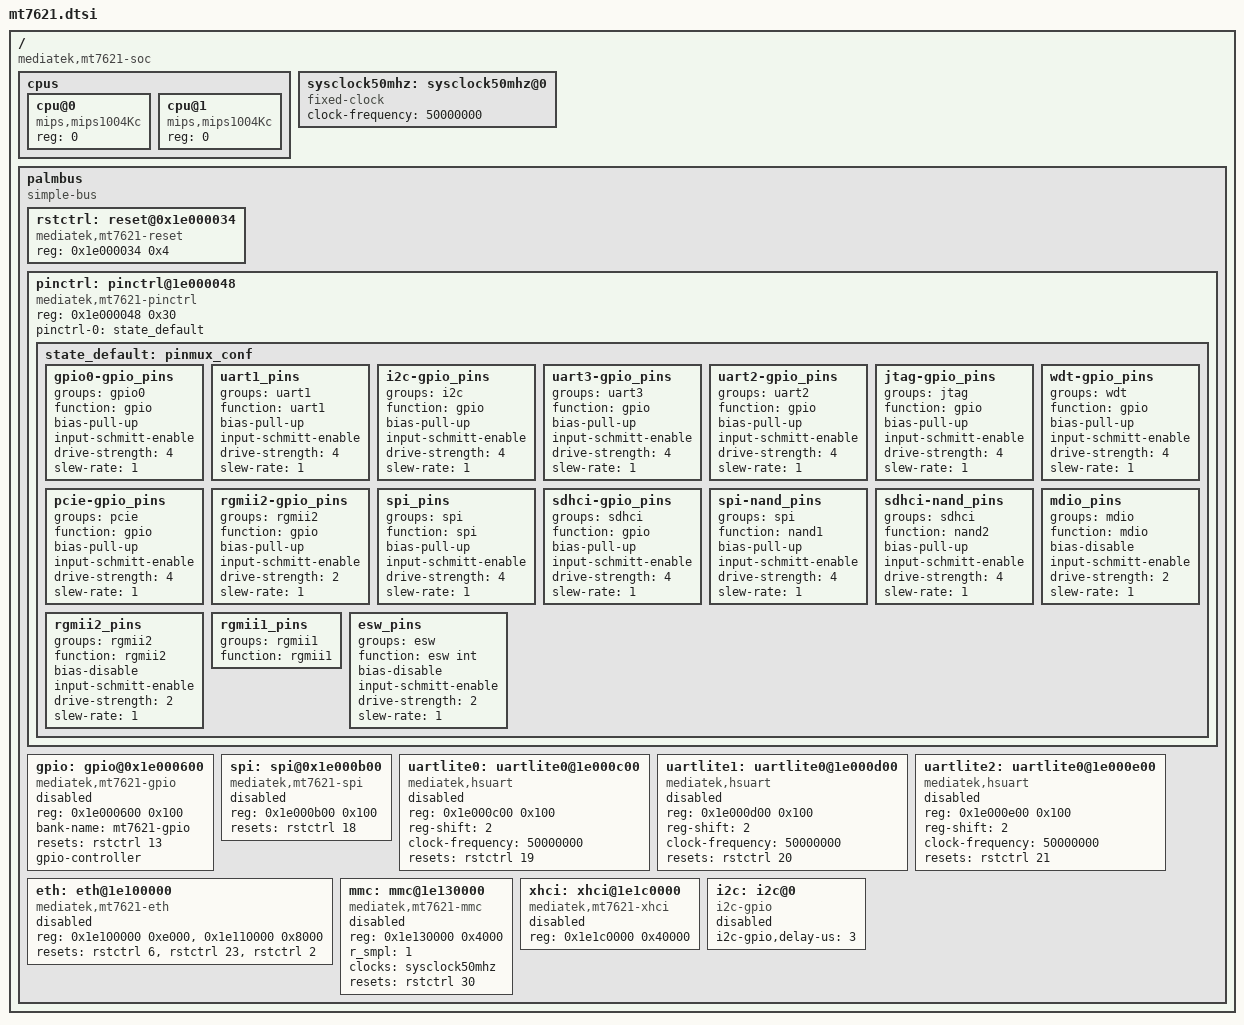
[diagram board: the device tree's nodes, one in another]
// SPDX-License-Identifier: GPL-2.0+
/*
 * Copyright (C) 2018 MediaTek Inc.
 *
 * Author: Weijie Gao <weijie.gao@mediatek.com>
 */

#include "skeleton.dtsi"

/ {
	compatible = "mediatek,mt7621-soc";

	#address-cells = <1>;
	#size-cells = <1>;

	cpus {
		#address-cells = <1>;
		#size-cells = <0>;

		cpu@0 {
			device_type = "cpu";
			compatible = "mips,mips1004Kc";
			reg = <0>;
		};

		cpu@1 {
			device_type = "cpu";
			compatible = "mips,mips1004Kc";
			reg = <0>;
		};
	};

	sysclock50mhz: sysclock50mhz@0 {
		compatible = "fixed-clock";

		clock-frequency = <50000000>;

		#clock-cells = <0>;
	};

	palmbus {
		compatible = "simple-bus";
		ranges;

		#address-cells = <1>;
		#size-cells = <1>;

		rstctrl: reset@0x1e000034 {
			compatible = "mediatek,mt7621-reset";
			reg = <0x1e000034 0x4>;

			status = "okay";

			#reset-cells = <1>;
		};

		pinctrl: pinctrl@1e000048 {
			compatible = "mediatek,mt7621-pinctrl";
			reg = <0x1e000048 0x30>;

			pinctrl-names = "default";
			pinctrl-0 = <&state_default>;

			state_default: pinmux_conf {
				gpio0-gpio_pins {
					groups = "gpio0";
					function = "gpio";
					bias-pull-up;
					input-schmitt-enable;
					drive-strength = <4>;
					slew-rate = <1>;
				};

				uart1_pins {
					groups = "uart1";
					function = "uart1";
					bias-pull-up;
					input-schmitt-enable;
					drive-strength = <4>;
					slew-rate = <1>;
				};

				i2c-gpio_pins {
					groups = "i2c";
					function = "gpio";
					bias-pull-up;
					input-schmitt-enable;
					drive-strength = <4>;
					slew-rate = <1>;
				};

				uart3-gpio_pins {
					groups = "uart3";
					function = "gpio";
					bias-pull-up;
					input-schmitt-enable;
					drive-strength = <4>;
					slew-rate = <1>;
				};

				uart2-gpio_pins {
					groups = "uart2";
					function = "gpio";
					bias-pull-up;
					input-schmitt-enable;
					drive-strength = <4>;
					slew-rate = <1>;
				};

				jtag-gpio_pins {
					groups = "jtag";
					function = "gpio";
					bias-pull-up;
					input-schmitt-enable;
					drive-strength = <4>;
					slew-rate = <1>;
				};

				wdt-gpio_pins {
					groups = "wdt";
					function = "gpio";
					bias-pull-up;
					input-schmitt-enable;
					drive-strength = <4>;
					slew-rate = <1>;
				};

				pcie-gpio_pins {
					groups = "pcie";
					function = "gpio";
					bias-pull-up;
					input-schmitt-enable;
					drive-strength = <4>;
					slew-rate = <1>;
				};

				rgmii2-gpio_pins {
					groups = "rgmii2";
					function = "gpio";
					bias-pull-up;
					input-schmitt-enable;
					drive-strength = <2>;
					slew-rate = <1>;
				};

				spi_pins {
					groups = "spi";
					function = "spi";
					bias-pull-up;
					input-schmitt-enable;
					drive-strength = <4>;
					slew-rate = <1>;
				};

				sdhci-gpio_pins {
					groups = "sdhci";
					function = "gpio";
					bias-pull-up;
					input-schmitt-enable;
					drive-strength = <4>;
					slew-rate = <1>;
				};

				spi-nand_pins {
					groups = "spi";
					function = "nand1";
					bias-pull-up;
					input-schmitt-enable;
					drive-strength = <4>;
					slew-rate = <1>;
				};

				sdhci-nand_pins {
					groups = "sdhci";
					function = "nand2";
					bias-pull-up;
					input-schmitt-enable;
					drive-strength = <4>;
					slew-rate = <1>;
				};

				mdio_pins {
					groups = "mdio";
					function = "mdio";
					bias-disable;
					input-schmitt-enable;
					drive-strength = <2>;
					slew-rate = <1>;
				};

				rgmii2_pins {
					groups = "rgmii2";
					function = "rgmii2";
					bias-disable;
					input-schmitt-enable;
					drive-strength = <2>;
					slew-rate = <1>;
				};

				rgmii1_pins {
					groups = "rgmii1";
					function = "rgmii1";
				};

				esw_pins {
					groups = "esw";
					function = "esw int";
					bias-disable;
					input-schmitt-enable;
					drive-strength = <2>;
					slew-rate = <1>;
				};
			};
		};

		gpio: gpio@0x1e000600 {
			compatible = "mediatek,mt7621-gpio";
			reg = <0x1e000600 0x100>;

			bank-name = "mt7621-gpio";
			resets = <&rstctrl 13>;

			status = "disabled";
			gpio-controller;
			#gpio-cells = <2>;
		};

		spi: spi@0x1e000b00 {
			compatible = "mediatek,mt7621-spi";
			reg = <0x1e000b00 0x100>;

			resets = <&rstctrl 18>;

			status = "disabled";

			#address-cells = <1>;
			#size-cells = <0>;
		};

		uartlite0: uartlite0@1e000c00 {
			compatible = "mediatek,hsuart", "ns16550";
			reg = <0x1e000c00 0x100>;
			reg-shift = <2>;
			clock-frequency = <50000000>;

			resets = <&rstctrl 19>;

			status = "disabled";
		};

		uartlite1: uartlite0@1e000d00 {
			compatible = "mediatek,hsuart", "ns16550";
			reg = <0x1e000d00 0x100>;
			reg-shift = <2>;
			clock-frequency = <50000000>;

			resets = <&rstctrl 20>;

			status = "disabled";
		};

		uartlite2: uartlite0@1e000e00 {
			compatible = "mediatek,hsuart", "ns16550";
			reg = <0x1e000e00 0x100>;
			reg-shift = <2>;
			clock-frequency = <50000000>;

			resets = <&rstctrl 21>;

			status = "disabled";
		};

		eth: eth@1e100000 {
			compatible = "mediatek,mt7621-eth";
			reg = <0x1e100000 0xe000>,
				<0x1e110000 0x8000>;
			reg-names = "fe", "gmac";

			resets = <&rstctrl 6>, <&rstctrl 23>, <&rstctrl 2>;
			reset-names = "fe", "gsw", "mcm";

			status = "disabled";

			#address-cells = <1>;
			#size-cells = <0>;
		};

		mmc: mmc@1e130000 {
			compatible = "mediatek,mt7621-mmc";
			reg = <0x1e130000 0x4000>;
			r_smpl = <1>;

			clocks = <&sysclock50mhz>;
			clock-names = "source";

			resets = <&rstctrl 30>;

			status = "disabled";
		};

		xhci: xhci@1e1c0000 {
			compatible = "mediatek,mt7621-xhci";
			reg = <0x1e1c0000 0x40000>;

			status = "disabled";

			#address-cells = <1>;
			#size-cells = <0>;
		};

		i2c: i2c@0 {
			compatible = "i2c-gpio";
			i2c-gpio,delay-us = <3>;
			status = "disabled";

			#address-cells = <1>;
			#size-cells = <0>;
		};
	};
};
